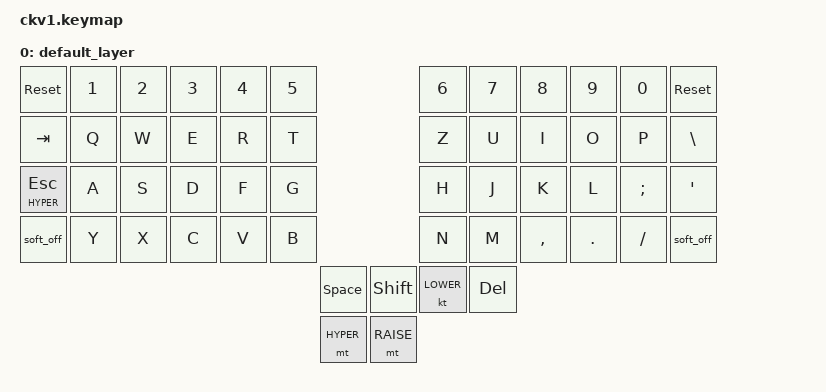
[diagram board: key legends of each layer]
#include <behaviors.dtsi>
#include <dt-bindings/zmk/keys.h>
#include <dt-bindings/zmk/outputs.h>
#include <dt-bindings/zmk/bt.h>

#define DEFAULT 0
#define LOWER   1
#define RAISE   2
#define ADJUST  3
#define HYPER   4


/ {


        conditional_layers {
                compatible = "zmk,conditional-layers";

                tri_layer {
                        if-layers  = <1 2>;
                        then-layer = <3>;
                };
        };

        keymap {
                compatible = "zmk,keymap";

                default_layer {
   /* QWERTY
 * .------------------------------------------------------------------------------------------------------------------.
 * |  `   |   1  |   2  |   3  |   4  |   5  |                              |   6  |   7  |   8  |   9  |   0  | PScr |
 * |-------------+------+------+------+------+------+------+-+-------+------+------+------+------+------+------+------|
 * | ESC  |   Q  |   W  |   E  |   R  |   T  |                              |   Z  |   U  |   I  |   O  |   P  |  \   |
 * |-------------+------+------+------+------+------+------+-+-------+------+------+------+------+------+------+------|
 * | Tab  |   A  |   S  |   D  |   F  |   G  |                              |   H  |   J  |   K  |   L  |   ;  |  '   |
 * |-------------+------+------+------+------+------+------+-+-------+------+------+------+------+------+------+------|
 * |      |   Y  |   X  |   C  |   V  |   B  |                              |   N  |   M  |   ,  |   .  |   /  |      |
 * |-------------+------+------+------+------+------+------+-+-------+------+------+------+------+------+------+------|
 * |                                         | Space| Shift| | Lower | Del  |                                         |
 * |-------------+------+------+------+------+------+------+-+-------+------+------+------+------+------+------+------|
 * |                                                | Hyper| | Raise |                                                |
 * .------------------------------------------------------------------------------------------------------------------.
 */
                        bindings = <
&sys_reset    &kp  N1    &kp  N2     &kp  N3     &kp  N4    &kp  N5                                                                        &kp  N6  &kp  N7    &kp  N8     &kp  N9    &kp  N0       &sys_reset
&kp  TAB      &kp  Q     &kp  W      &kp  E      &kp  R     &kp  T                                                                         &kp  Z   &kp  U     &kp  I      &kp  O     &kp  P        &kp  BSLH
&lt HYPER ESC &kp  A     &kp  S      &kp  D      &kp  F     &kp  G                                                                         &kp  H   &kp  J     &kp  K      &kp  L     &kp  SEMI     &kp  SQT
&soft_off     &kp  Y     &kp  X      &kp  C      &kp  V     &kp  B                                                                         &kp  N   &kp  M     &kp  COMMA  &kp  DOT   &kp  SLASH    &soft_off
                                                                               &kp  Space    &kp  Shift   &kt  LOWER  &kp  DEL 
                                                                                             &mt HYPER    &mt  RAISE
                        >;
                };

                lower_layer {
/* QWERTY
 * .------------------------------------------------------------------------------------------------------------------.
 * |  `   |   1  |   2  |   3  |   4  |   5  |                              |   6  |   7  |   8  |   9  |   0  | PScr |
 * |-------------+------+------+------+------+------+------+-+-------+------+------+------+------+------+------+------|
 * | ESC  |   Q  |   W  |   E  |   R  |   T  |                              |   Z  |   U  |   I  |   O  |   P  |  \   |
 * |-------------+------+------+------+------+------+------+-+-------+------+------+------+------+------+------+------|
 * | Tab  |   A  |   S  |   D  |   F  |   G  |                              |   H  |   J  |   K  |   L  |   ;  |  '   |
 * |-------------+------+------+------+------+------+------+-+-------+------+------+------+------+------+------+------|
 * |      |   Y  |   X  |   C  |   V  |   B  |                              |   N  |   M  |   ,  |   .  |   /  |      |
 * |-------------+------+------+------+------+------+------+-+-------+------+------+------+------+------+------+------|
 * |                                         | Space| Shift| | Lower | Del  |                                         |
 * |-------------+------+------+------+------+------+------+-+-------+------+------+------+------+------+------+------|
 * |                                                | Hyper| | Raise |                                                |
 * .------------------------------------------------------------------------------------------------------------------.
 */
                        bindings = <
&sys_reset    &kp  N1    &kp  N2     &kp  N3     &kp  N4    &kp  N5                                                                        &kp  N6  &kp  N7    &kp  N8     &kp  N9    &kp  N0       &sys_reset
&kp  TAB      &kp  Q     &kp  W      &kp  E      &kp  R     &kp  T                                                                         &kp  Z   &kp  U     &kp  I      &kp  O     &kp  P        &kp  BSLH
&lt HYPER ESC &kp  A     &kp  S      &kp  D      &kp  F     &kp  G                                                                         &kp  H   &kp  J     &kp  K      &kp  L     &kp  SEMI     &kp  SQT
&soft_off     &kp  Y     &kp  X      &kp  C      &kp  V     &kp  B                                                                         &kp  N   &kp  M     &kp  COMMA  &kp  DOT   &kp  SLASH    &soft_off
                                                                               &kp  Space    &kp  Shift   &kt  LOWER  &kp  DEL 
                                                                                             &mt HYPER    &mt  RAISE

                raise_layer {
/* QWERTY
 * .------------------------------------------------------------------------------------------------------------------.
 * |  `   |   1  |   2  |   3  |   4  |   5  |                              |   6  |   7  |   8  |   9  |   0  | PScr |
 * |-------------+------+------+------+------+------+------+-+-------+------+------+------+------+------+------+------|
 * | ESC  |   Q  |   W  |   E  |   R  |   T  |                              |   Z  |   U  |   I  |   O  |   P  |  \   |
 * |-------------+------+------+------+------+------+------+-+-------+------+------+------+------+------+------+------|
 * | Tab  |   A  |   S  |   D  |   F  |   G  |                              |   H  |   J  |   K  |   L  |   ;  |  '   |
 * |-------------+------+------+------+------+------+------+-+-------+------+------+------+------+------+------+------|
 * |      |   Y  |   X  |   C  |   V  |   B  |                              |   N  |   M  |   ,  |   .  |   /  |      |
 * |-------------+------+------+------+------+------+------+-+-------+------+------+------+------+------+------+------|
 * |                                         | Space| Shift| | Lower | Del  |                                         |
 * |-------------+------+------+------+------+------+------+-+-------+------+------+------+------+------+------+------|
 * |                                                | Hyper| | Raise |                                                |
 * .------------------------------------------------------------------------------------------------------------------.
 */
                        bindings = <
&sys_reset    &kp  N1    &kp  N2     &kp  N3     &kp  N4    &kp  N5                                                                        &kp  N6  &kp  N7    &kp  N8     &kp  N9    &kp  N0       &sys_reset
&kp  TAB      &kp  Q     &kp  W      &kp  E      &kp  R     &kp  T                                                                         &kp  Z   &kp  U     &kp  I      &kp  O     &kp  P        &kp  BSLH
&lt HYPER ESC &kp  A     &kp  S      &kp  D      &kp  F     &kp  G                                                                         &kp  H   &kp  J     &kp  K      &kp  L     &kp  SEMI     &kp  SQT
&soft_off     &kp  Y     &kp  X      &kp  C      &kp  V     &kp  B                                                                         &kp  N   &kp  M     &kp  COMMA  &kp  DOT   &kp  SLASH    &soft_off
                                                                               &kp  Space    &kp  Shift   &kt  LOWER  &kp  DEL 
                                                                                             &mt HYPER    &mt  RAISE
                        >;
                };
                adjust_layer {
/* QWERTY
 * .------------------------------------------------------------------------------------------------------------------.
 * |  `   |   1  |   2  |   3  |   4  |   5  |                              |   6  |   7  |   8  |   9  |   0  | PScr |
 * |-------------+------+------+------+------+------+------+-+-------+------+------+------+------+------+------+------|
 * | ESC  |   Q  |   W  |   E  |   R  |   T  |                              |   Z  |   U  |   I  |   O  |   P  |  \   |
 * |-------------+------+------+------+------+------+------+-+-------+------+------+------+------+------+------+------|
 * | Tab  |   A  |   S  |   D  |   F  |   G  |                              |   H  |   J  |   K  |   L  |   ;  |  '   |
 * |-------------+------+------+------+------+------+------+-+-------+------+------+------+------+------+------+------|
 * |      |   Y  |   X  |   C  |   V  |   B  |                              |   N  |   M  |   ,  |   .  |   /  |      |
 * |-------------+------+------+------+------+------+------+-+-------+------+------+------+------+------+------+------|
 * |                                         | Space| Shift| | Lower | Del  |                                         |
 * |-------------+------+------+------+------+------+------+-+-------+------+------+------+------+------+------+------|
 * |                                                | Hyper| | Raise |                                                |
 * .------------------------------------------------------------------------------------------------------------------.
                        bindings = <
&sys_reset    &kp  N1    &kp  N2     &kp  N3     &kp  N4    &kp  N5                                                                        &kp  N6  &kp  N7    &kp  N8     &kp  N9    &kp  N0       &sys_reset
&kp  TAB      &kp  Q     &kp  W      &kp  E      &kp  R     &kp  T                                                                         &kp  Z   &kp  U     &kp  I      &kp  O     &kp  P        &kp  BSLH
&lt HYPER ESC &kp  A     &kp  S      &kp  D      &kp  F     &kp  G                                                                         &kp  H   &kp  J     &kp  K      &kp  L     &kp  SEMI     &kp  SQT
&soft_off     &kp  Y     &kp  X      &kp  C      &kp  V     &kp  B                                                                         &kp  N   &kp  M     &kp  COMMA  &kp  DOT   &kp  SLASH    &soft_off
                                                                               &kp  Space    &kp  Shift   &kt  LOWER  &kp  DEL 
                                                                                             &mt HYPER    &mt  RAISE
/* QWERTY
 * .------------------------------------------------------------------------------------------------------------------.
 * |  `   |   1  |   2  |   3  |   4  |   5  |                              |   6  |   7  |   8  |   9  |   0  | PScr |
 * |-------------+------+------+------+------+------+------+-+-------+------+------+------+------+------+------+------|
 * | ESC  |   Q  |   W  |   E  |   R  |   T  |                              |   Z  |   U  |   I  |   O  |   P  |  \   |
 * |-------------+------+------+------+------+------+------+-+-------+------+------+------+------+------+------+------|
 * | Tab  |   A  |   S  |   D  |   F  |   G  |                              |   H  |   J  |   K  |   L  |   ;  |  '   |
 * |-------------+------+------+------+------+------+------+-+-------+------+------+------+------+------+------+------|
 * |      |   Y  |   X  |   C  |   V  |   B  |                              |   N  |   M  |   ,  |   .  |   /  |      |
 * |-------------+------+------+------+------+------+------+-+-------+------+------+------+------+------+------+------|
 * |                                         | Space| Shift| | Lower | Del  |                                         |
 * |-------------+------+------+------+------+------+------+-+-------+------+------+------+------+------+------+------|
 * |                                                | Hyper| | Raise |                                                |
 * .------------------------------------------------------------------------------------------------------------------.
 */
                        bindings = <
&sys_reset    &kp  N1    &kp  N2     &kp  N3     &kp  N4    &kp  N5                                                                        &kp  N6  &kp  N7    &kp  N8     &kp  N9    &kp  N0       &sys_reset
&kp  TAB      &kp  Q     &kp  W      &kp  E      &kp  R     &kp  T                                                                         &kp  Z   &kp  U     &kp  I      &kp  O     &kp  P        &kp  BSLH
&lt HYPER ESC &kp  A     &kp  S      &kp  D      &kp  F     &kp  G                                                                         &kp  H   &kp  J     &kp  K      &kp  L     &kp  SEMI     &kp  SQT
&soft_off     &kp  Y     &kp  X      &kp  C      &kp  V     &kp  B                                                                         &kp  N   &kp  M     &kp  COMMA  &kp  DOT   &kp  SLASH    &soft_off
                                                                               &kp  Space    &kp  Shift   &kt  LOWER  &kp  DEL 
                                                                                             &mt HYPER    &mt  RAISE
                        >;
                };


    };
};
